VERSION ""

NS_ :

BS_:

BU_:
    NEO
    MCU
    GTW
    EPAS
    DI
    ESP
    SBW
    STW
	APP
	DAS

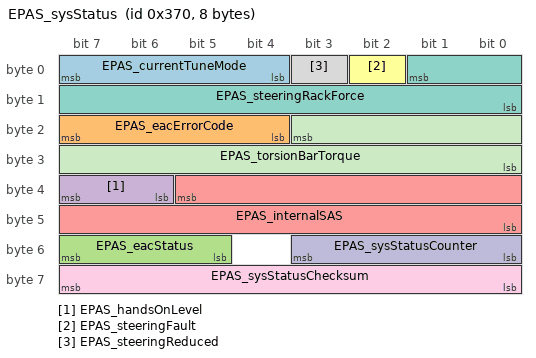
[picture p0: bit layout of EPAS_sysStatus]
BO_ 880 EPAS_sysStatus: 8 EPAS
 SG_ EPAS_currentTuneMode : 7|4@0+ (1,0) [8|15] ""  NEO
 SG_ EPAS_eacErrorCode : 23|4@0+ (1,0) [-1|16] ""  NEO
 SG_ EPAS_eacStatus : 55|3@0+ (1,0) [5|7] ""  NEO
 SG_ EPAS_handsOnLevel : 39|2@0+ (1,0) [-1|4] ""  NEO
 SG_ EPAS_internalSAS : 37|14@0+ (0.1,-819.200012) [0|0] "deg"  NEO
 SG_ EPAS_steeringFault : 2|1@0+ (1,0) [-1|2] ""  NEO
 SG_ EPAS_steeringRackForce : 1|10@0+ (50,-25575) [0|0] "N" NEO
 SG_ EPAS_steeringReduced : 3|1@0+ (1,0) [-1|2] ""  NEO
 SG_ EPAS_sysStatusChecksum : 63|8@0+ (1,0) [0|255] ""  NEO
 SG_ EPAS_sysStatusCounter : 51|4@0+ (1,0) [0|15] ""  NEO
 SG_ EPAS_torsionBarTorque : 19|12@0+ (0.01,-20.5) [0|0] "Nm"  NEO

VAL_ 880 EPAS_currentTuneMode 1 "DM_COMFORT" 3 "DM_SPORT" 2 "DM_STANDARD" 0 "FAIL_SAFE_DEFAULT" 4 "RWD_COMFORT" 6 "RWD_SPORT" 5 "RWD_STANDARD" 7 "UNAVAILABLE" ;
VAL_ 880 EPAS_eacErrorCode 14 "EAC_ERROR_EPB_INHIBIT" 3 "EAC_ERROR_HANDS_ON" 7 "EAC_ERROR_HIGH_ANGLE_RATE_REQ" 9 "EAC_ERROR_HIGH_ANGLE_RATE_SAFETY" 6 "EAC_ERROR_HIGH_ANGLE_REQ" 8 "EAC_ERROR_HIGH_ANGLE_SAFETY" 10 "EAC_ERROR_HIGH_MMOT_SAFETY" 11 "EAC_ERROR_HIGH_TORSION_SAFETY" 0 "EAC_ERROR_IDLE" 12 "EAC_ERROR_LOW_ASSIST" 2 "EAC_ERROR_MAX_SPEED" 1 "EAC_ERROR_MIN_SPEED" 13 "EAC_ERROR_PINION_VEL_DIFF" 4 "EAC_ERROR_TMP_FAULT" 5 "EAR_ERROR_MAX_STEER_DELTA" 15 "SNA" ;
VAL_ 880 EPAS_eacStatus 2 "EAC_ACTIVE" 1 "EAC_AVAILABLE" 3 "EAC_FAULT" 0 "EAC_INHIBITED" 4 "SNA" ;
VAL_ 880 EPAS_handsOnLevel 0 "0" 1 "1" 2 "2" 3 "3" ;
VAL_ 880 EPAS_steeringFault 1 "FAULT" 0 "NO_FAULT" ;
VAL_ 880 EPAS_steeringRackForce 1022 "NOT_IN_SPEC" 1023 "SNA" ;
VAL_ 880 EPAS_steeringReduced 0 "NORMAL_ASSIST" 1 "REDUCED_ASSIST" ;
VAL_ 880 EPAS_torsionBarTorque 0 "SEE_SPECIFICATION" 4095 "SNA" 4094 "UNDEFINABLE_DATA" ;
